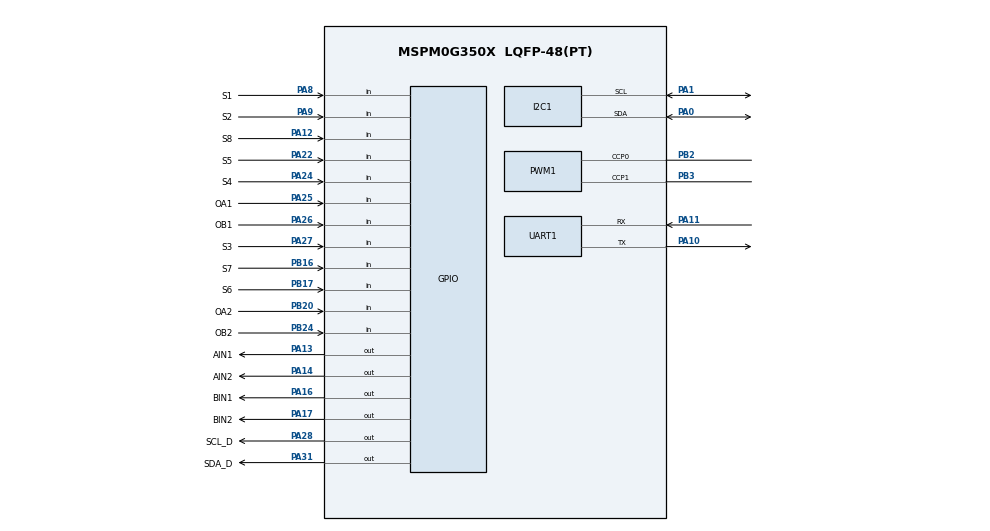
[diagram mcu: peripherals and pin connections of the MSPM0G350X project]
/**
 * @cliArgs --device "MSPM0G350X" --part "Default" --package "LQFP-48(PT)" --product "mspm0_sdk@2.10.00.04"
 * @versions {"tool":"1.26.2+4477"}
 */

/**
 * Import the modules used in this configuration.
 */
const ADC12   = scripting.addModule("/ti/driverlib/ADC12", {}, false);
const ADC121  = ADC12.addInstance();
const GPIO    = scripting.addModule("/ti/driverlib/GPIO", {}, false);
const GPIO1   = GPIO.addInstance();
const GPIO2   = GPIO.addInstance();
const GPIO3   = GPIO.addInstance();
const GPIO4   = GPIO.addInstance();
const GPIO5   = GPIO.addInstance();
const I2C     = scripting.addModule("/ti/driverlib/I2C", {}, false);
const I2C1    = I2C.addInstance();
const PWM     = scripting.addModule("/ti/driverlib/PWM", {}, false);
const PWM1    = PWM.addInstance();
const SYSCTL  = scripting.addModule("/ti/driverlib/SYSCTL");
const SYSTICK = scripting.addModule("/ti/driverlib/SYSTICK");
const TIMER   = scripting.addModule("/ti/driverlib/TIMER", {}, false);
const TIMER1  = TIMER.addInstance();
const UART    = scripting.addModule("/ti/driverlib/UART", {}, false);
const UART1   = UART.addInstance();

/**
 * Write custom configuration values to the imported modules.
 */
const divider9       = system.clockTree["UDIV"];
divider9.divideValue = 2;

const gate7  = system.clockTree["MFCLKGATE"];
gate7.enable = true;

const multiplier2         = system.clockTree["PLL_QDIV"];
multiplier2.multiplyValue = 4;

const mux4       = system.clockTree["EXHFMUX"];
mux4.inputSelect = "EXHFMUX_XTAL";

const mux8       = system.clockTree["HSCLKMUX"];
mux8.inputSelect = "HSCLKMUX_SYSPLL0";

const mux12       = system.clockTree["SYSPLLMUX"];
mux12.inputSelect = "zSYSPLLMUX_HFCLK";

const pinFunction4       = system.clockTree["HFXT"];
pinFunction4.inputFreq   = 40;
pinFunction4.enable      = true;
pinFunction4.HFXTStartup = 10;

ADC121.repeatMode                        = true;
ADC121.$name                             = "ADC0_VOLTAGE";
ADC121.adcPin0Config.$name               = "ti_driverlib_gpio_GPIOPinGeneric0";
ADC121.adcPin0Config.hideOutputInversion = scripting.forceWrite(false);

const Board = scripting.addModule("/ti/driverlib/Board", {}, false);

GPIO1.$name                               = "ENCODER";
GPIO1.associatedPins.create(4);
GPIO1.associatedPins[0].$name             = "OA1";
GPIO1.associatedPins[0].direction         = "INPUT";
GPIO1.associatedPins[0].assignedPort      = "PORTA";
GPIO1.associatedPins[0].interruptPriority = "0";
GPIO1.associatedPins[0].polarity          = "RISE";
GPIO1.associatedPins[0].assignedPin       = "25";
GPIO1.associatedPins[0].interruptEn       = true;
GPIO1.associatedPins[0].pin.$assign       = "PA25";
GPIO1.associatedPins[1].$name             = "OB2";
GPIO1.associatedPins[1].direction         = "INPUT";
GPIO1.associatedPins[1].assignedPort      = "PORTB";
GPIO1.associatedPins[1].interruptPriority = "0";
GPIO1.associatedPins[1].polarity          = "RISE";
GPIO1.associatedPins[1].assignedPin       = "24";
GPIO1.associatedPins[1].interruptEn       = true;
GPIO1.associatedPins[1].pin.$assign       = "PB24";
GPIO1.associatedPins[2].$name             = "OB1";
GPIO1.associatedPins[2].direction         = "INPUT";
GPIO1.associatedPins[2].assignedPort      = "PORTA";
GPIO1.associatedPins[2].interruptEn       = true;
GPIO1.associatedPins[2].interruptPriority = "0";
GPIO1.associatedPins[2].polarity          = "RISE";
GPIO1.associatedPins[2].assignedPin       = "26";
GPIO1.associatedPins[2].pin.$assign       = "PA26";
GPIO1.associatedPins[3].$name             = "OA2";
GPIO1.associatedPins[3].direction         = "INPUT";
GPIO1.associatedPins[3].assignedPort      = "PORTB";
GPIO1.associatedPins[3].interruptEn       = true;
GPIO1.associatedPins[3].interruptPriority = "0";
GPIO1.associatedPins[3].polarity          = "RISE";
GPIO1.associatedPins[3].assignedPin       = "20";
GPIO1.associatedPins[3].pin.$assign       = "PB20";

GPIO2.$name                          = "MOTOR";
GPIO2.associatedPins.create(4);
GPIO2.associatedPins[0].$name        = "AIN1";
GPIO2.associatedPins[0].assignedPort = "PORTA";
GPIO2.associatedPins[0].assignedPin  = "13";
GPIO2.associatedPins[0].pin.$assign  = "PA13";
GPIO2.associatedPins[1].$name        = "AIN2";
GPIO2.associatedPins[1].assignedPort = "PORTA";
GPIO2.associatedPins[1].assignedPin  = "14";
GPIO2.associatedPins[1].pin.$assign  = "PA14";
GPIO2.associatedPins[2].$name        = "BIN1";
GPIO2.associatedPins[2].assignedPort = "PORTA";
GPIO2.associatedPins[2].assignedPin  = "16";
GPIO2.associatedPins[2].pin.$assign  = "PA16";
GPIO2.associatedPins[3].$name        = "BIN2";
GPIO2.associatedPins[3].assignedPort = "PORTA";
GPIO2.associatedPins[3].assignedPin  = "17";
GPIO2.associatedPins[3].pin.$assign  = "PA17";

GPIO3.$name                          = "GYRO";
GPIO3.associatedPins[0].initialValue = "SET";
GPIO3.associatedPins[0].assignedPort = "PORTA";
GPIO3.associatedPins[0].$name        = "GYRO_INT";
GPIO3.associatedPins[0].direction    = "INPUT";
GPIO3.associatedPins[0].assignedPin  = "7";

GPIO4.$name                              = "TRACK";
GPIO4.associatedPins.create(8);
GPIO4.associatedPins[0].$name            = "S1";
GPIO4.associatedPins[0].direction        = "INPUT";
GPIO4.associatedPins[0].assignedPort     = "PORTA";
GPIO4.associatedPins[0].assignedPin      = "8";
GPIO4.associatedPins[0].internalResistor = "PULL_UP";
GPIO4.associatedPins[0].pin.$assign      = "PA8";
GPIO4.associatedPins[1].$name            = "S2";
GPIO4.associatedPins[1].direction        = "INPUT";
GPIO4.associatedPins[1].assignedPort     = "PORTA";
GPIO4.associatedPins[1].assignedPin      = "9";
GPIO4.associatedPins[1].internalResistor = "PULL_UP";
GPIO4.associatedPins[1].pin.$assign      = "PA9";
GPIO4.associatedPins[2].direction        = "INPUT";
GPIO4.associatedPins[2].assignedPort     = "PORTA";
GPIO4.associatedPins[2].$name            = "S5";
GPIO4.associatedPins[2].internalResistor = "PULL_UP";
GPIO4.associatedPins[2].assignedPin      = "22";
GPIO4.associatedPins[2].pin.$assign      = "PA22";
GPIO4.associatedPins[3].$name            = "S6";
GPIO4.associatedPins[3].direction        = "INPUT";
GPIO4.associatedPins[3].internalResistor = "PULL_UP";
GPIO4.associatedPins[3].assignedPort     = "PORTB";
GPIO4.associatedPins[3].assignedPin      = "17";
GPIO4.associatedPins[3].pin.$assign      = "PB17";
GPIO4.associatedPins[4].$name            = "S7";
GPIO4.associatedPins[4].direction        = "INPUT";
GPIO4.associatedPins[4].internalResistor = "PULL_UP";
GPIO4.associatedPins[4].assignedPort     = "PORTB";
GPIO4.associatedPins[4].assignedPin      = "16";
GPIO4.associatedPins[4].pin.$assign      = "PB16";
GPIO4.associatedPins[5].$name            = "S8";
GPIO4.associatedPins[5].direction        = "INPUT";
GPIO4.associatedPins[5].internalResistor = "PULL_UP";
GPIO4.associatedPins[5].assignedPort     = "PORTA";
GPIO4.associatedPins[5].assignedPin      = "12";
GPIO4.associatedPins[5].pin.$assign      = "PA12";
GPIO4.associatedPins[6].$name            = "S3";
GPIO4.associatedPins[6].direction        = "INPUT";
GPIO4.associatedPins[6].assignedPort     = "PORTA";
GPIO4.associatedPins[6].assignedPin      = "27";
GPIO4.associatedPins[6].internalResistor = "PULL_UP";
GPIO4.associatedPins[6].pin.$assign      = "PA27";
GPIO4.associatedPins[7].$name            = "S4";
GPIO4.associatedPins[7].direction        = "INPUT";
GPIO4.associatedPins[7].assignedPort     = "PORTA";
GPIO4.associatedPins[7].assignedPin      = "24";
GPIO4.associatedPins[7].internalResistor = "PULL_UP";
GPIO4.associatedPins[7].pin.$assign      = "PA24";

GPIO5.$name                          = "OLED";
GPIO5.associatedPins.create(2);
GPIO5.associatedPins[0].$name        = "SCL_D";
GPIO5.associatedPins[0].assignedPort = "PORTA";
GPIO5.associatedPins[0].assignedPin  = "28";
GPIO5.associatedPins[0].initialValue = "SET";
GPIO5.associatedPins[0].pin.$assign  = "PA28";
GPIO5.associatedPins[1].$name        = "SDA_D";
GPIO5.associatedPins[1].assignedPort = "PORTA";
GPIO5.associatedPins[1].assignedPin  = "31";
GPIO5.associatedPins[1].initialValue = "SET";
GPIO5.associatedPins[1].pin.$assign  = "PA31";

I2C1.$name                           = "I2C_0";
I2C1.basicEnableController           = true;
I2C1.basicControllerStandardBusSpeed = "Fast";
I2C1.peripheral.sdaPin.$assign       = "PA0";
I2C1.peripheral.sclPin.$assign       = "PA1";
I2C1.sdaPinConfig.$name              = "ti_driverlib_gpio_GPIOPinGeneric5";
I2C1.sclPinConfig.$name              = "ti_driverlib_gpio_GPIOPinGeneric6";

PWM1.$name                              = "PWM_T";
PWM1.clockDivider                       = 8;
PWM1.timerStartTimer                    = true;
PWM1.peripheral.$assign                 = "TIMG6";
PWM1.peripheral.ccp0Pin.$assign         = "PB2";
PWM1.peripheral.ccp1Pin.$assign         = "PB3";
PWM1.PWM_CHANNEL_0.$name                = "ti_driverlib_pwm_PWMTimerCC0";
PWM1.PWM_CHANNEL_0.invert               = true;
PWM1.PWM_CHANNEL_1.$name                = "ti_driverlib_pwm_PWMTimerCC1";
PWM1.PWM_CHANNEL_1.invert               = true;
PWM1.ccp0PinConfig.$name                = "ti_driverlib_gpio_GPIOPinGeneric3";
PWM1.ccp0PinConfig.direction            = scripting.forceWrite("OUTPUT");
PWM1.ccp0PinConfig.hideOutputInversion  = scripting.forceWrite(false);
PWM1.ccp0PinConfig.onlyInternalResistor = scripting.forceWrite(false);
PWM1.ccp0PinConfig.passedPeripheralType = scripting.forceWrite("Digital");
PWM1.ccp1PinConfig.$name                = "ti_driverlib_gpio_GPIOPinGeneric4";
PWM1.ccp1PinConfig.direction            = scripting.forceWrite("OUTPUT");
PWM1.ccp1PinConfig.hideOutputInversion  = scripting.forceWrite(false);
PWM1.ccp1PinConfig.onlyInternalResistor = scripting.forceWrite(false);
PWM1.ccp1PinConfig.passedPeripheralType = scripting.forceWrite("Digital");

SYSCTL.useHFCLK_Manual = true;
SYSCTL.MFCLKEn         = true;
SYSCTL.clockTreeEn     = true;

SYSTICK.periodEnable      = true;
SYSTICK.period            = 80;
SYSTICK.systickEnable     = true;
SYSTICK.interruptPriority = "0";

TIMER1.$name             = "TIMER_0";
TIMER1.interrupts        = ["ZERO"];
TIMER1.timerPeriod       = "1ms";
TIMER1.timerClkSrc       = "MFCLK";
TIMER1.timerClkPrescale  = 40;
TIMER1.timerMode         = "PERIODIC";
TIMER1.timerStartTimer   = true;
TIMER1.interruptPriority = "3";

UART1.$name                            = "UART_MS901M";
UART1.targetBaudRate                   = 115200;
UART1.peripheral.rxPin.$assign         = "PA11";
UART1.peripheral.txPin.$assign         = "PA10";
UART1.txPinConfig.direction            = scripting.forceWrite("OUTPUT");
UART1.txPinConfig.hideOutputInversion  = scripting.forceWrite(false);
UART1.txPinConfig.onlyInternalResistor = scripting.forceWrite(false);
UART1.txPinConfig.passedPeripheralType = scripting.forceWrite("Digital");
UART1.txPinConfig.$name                = "ti_driverlib_gpio_GPIOPinGeneric1";
UART1.rxPinConfig.hideOutputInversion  = scripting.forceWrite(false);
UART1.rxPinConfig.onlyInternalResistor = scripting.forceWrite(false);
UART1.rxPinConfig.passedPeripheralType = scripting.forceWrite("Digital");
UART1.rxPinConfig.$name                = "ti_driverlib_gpio_GPIOPinGeneric2";

const ProjectConfig              = scripting.addModule("/ti/project_config/ProjectConfig", {}, false);
ProjectConfig.migrationCondition = true;

/**
 * Pinmux solution for unlocked pins/peripherals. This ensures that minor changes to the automatic solver in a future
 * version of the tool will not impact the pinmux you originally saw.  These lines can be completely deleted in order to
 * re-solve from scratch.
 */
pinFunction4.peripheral.$suggestSolution           = "SYSCTL";
pinFunction4.peripheral.hfxInPin.$suggestSolution  = "PA5";
pinFunction4.peripheral.hfxOutPin.$suggestSolution = "PA6";
ADC121.peripheral.$suggestSolution                 = "ADC1";
ADC121.peripheral.adcPin0.$suggestSolution         = "PA15";
Board.peripheral.$suggestSolution                  = "DEBUGSS";
Board.peripheral.swclkPin.$suggestSolution         = "PA20";
Board.peripheral.swdioPin.$suggestSolution         = "PA19";
GPIO3.associatedPins[0].pin.$suggestSolution       = "PA7";
I2C1.peripheral.$suggestSolution                   = "I2C0";
TIMER1.peripheral.$suggestSolution                 = "TIMA0";
UART1.peripheral.$suggestSolution                  = "UART0";
